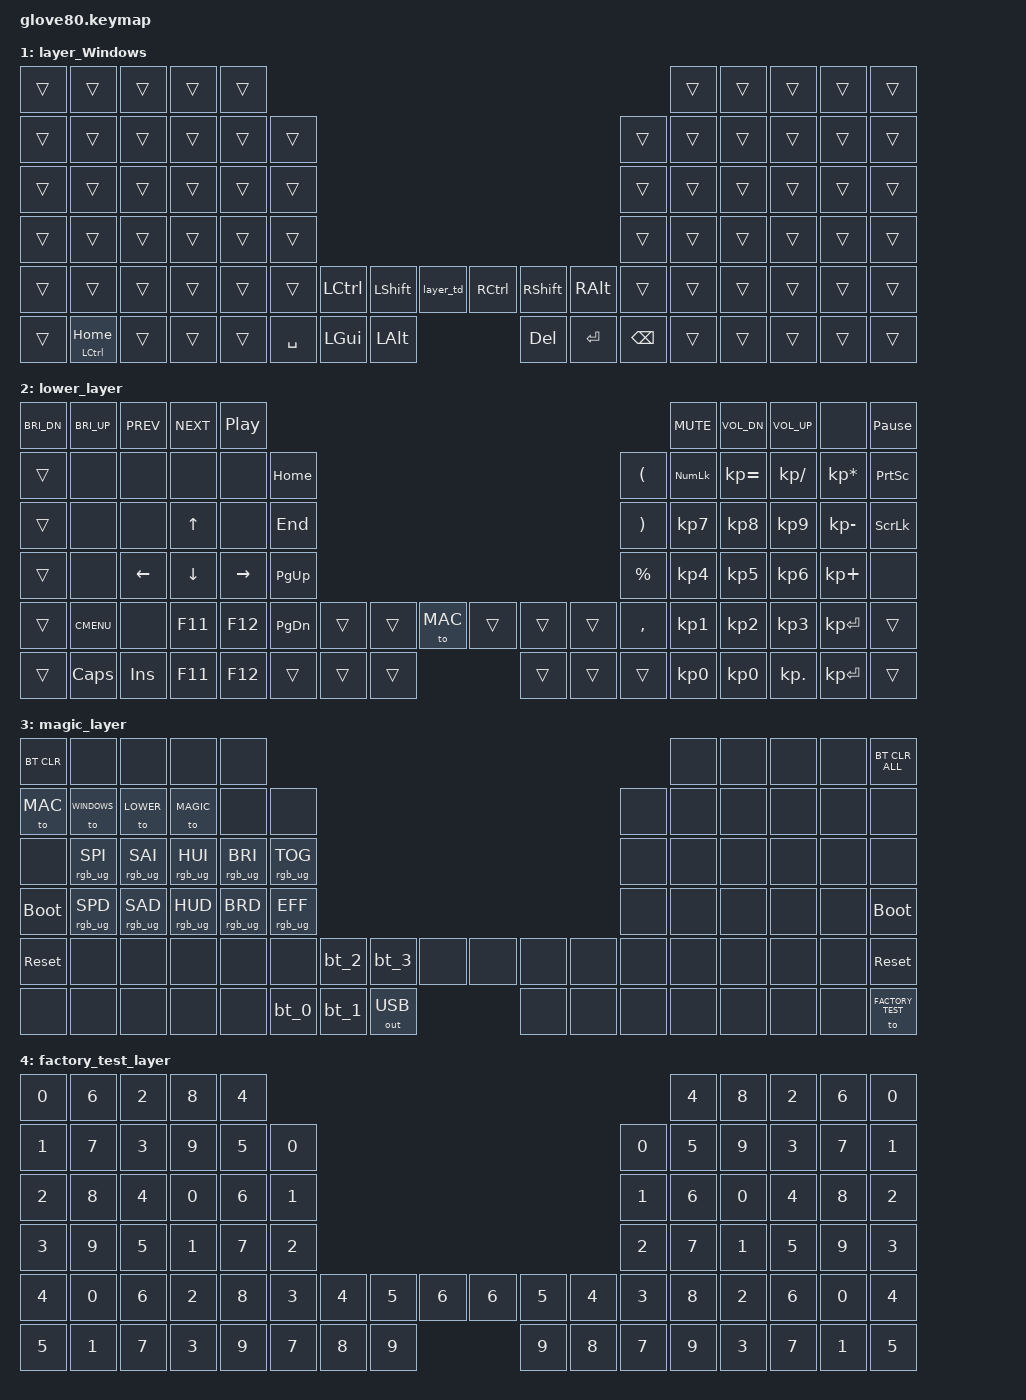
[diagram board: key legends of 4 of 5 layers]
/*
 * Copyright (c) 2020 The ZMK Contributors
 *
 * SPDX-License-Identifier: MIT
 */

#include <behaviors.dtsi>
#include <dt-bindings/zmk/keys.h>
#include <dt-bindings/zmk/bt.h>
#include <dt-bindings/zmk/ext_power.h>
#include <dt-bindings/zmk/outputs.h>
#include <dt-bindings/zmk/rgb.h>

#define HYPER LC(LS(LG(LALT)))

// layers
#define MAC 0
#define WINDOWS 1
#define LOWER 2
#define MAGIC 3
#define FACTORY_TEST 4

// My Personal defines
#define AS(keycode) &tk LS(keycode) keycode     // Autoshift Macro
#define KEYS_L 10 11 12 13 14 15 22 23 24 25 26 27 34 35 36 37 38 39 46 47 48 49 50 51 64 65 66 67 68  // left-hand keys
#define KEYS_R 16 17 18 19 20 21 28 29 30 31 32 33 40 41 42 43 44 45 58 59 60 61 62 63 75 76 77 78 79  // right-hand keys
#define THUMB_L 52 53 54 69 70 71
#define THUMB_R 55 56 57 72 73 74
#define HRM_KEYS_L 35 36 37 38
#define HRM_KEYS_R 41 42 43 44

#define LHRM &lh_pht_bal
#define RHRM &rh_pht_bal

/ {
    behaviors {
        // For the "layer" key, it'd nice to be able to use it as either a shift or a toggle.
        // Configure it as a tap dance, so the first tap (or hold) is a &mo and the second tap is a &to
        layer_td: tap_dance_0 {
            compatible = "zmk,behavior-tap-dance";
            label = "LAYER_TAP_DANCE";
            #binding-cells = <0>;
            tapping-term-ms = <200>;
            bindings = <&mo LOWER>, <&to LOWER>;
        };

        magic: magic_hold_tap {
            compatible = "zmk,behavior-hold-tap";
            label = "MAGIC_HOLD_TAP";
            #binding-cells = <2>;
            flavor = "tap-preferred";
            tapping-term-ms = <200>;
            bindings = <&mo>, <&rgb_ug_status_macro>;
        };
    };

    macros {
        rgb_ug_status_macro: rgb_ug_status_macro_0 {
            label = "RGB_UG_STATUS";
            compatible = "zmk,behavior-macro";
            #binding-cells = <0>;
            bindings
                = <&rgb_ug RGB_STATUS>;
        };

        bt_0: bt_profile_macro_0 {
            label = "BT_0";
            compatible = "zmk,behavior-macro";
            #binding-cells = <0>;
            bindings
                = <&out OUT_BLE>,
                  <&bt BT_SEL 0>;
        };

        bt_1: bt_profile_macro_1 {
            label = "BT_1";
            compatible = "zmk,behavior-macro";
            #binding-cells = <0>;
            bindings
                = <&out OUT_BLE>,
                  <&bt BT_SEL 1>;
        };

        bt_2: bt_profile_macro_2 {
            label = "BT_2";
            compatible = "zmk,behavior-macro";
            #binding-cells = <0>;
            bindings
                = <&out OUT_BLE>,
                  <&bt BT_SEL 2>;
        };

        bt_3: bt_profile_macro_3 {
            label = "BT_3";
            compatible = "zmk,behavior-macro";
            #binding-cells = <0>;
            bindings
                = <&out OUT_BLE>,
                  <&bt BT_SEL 3>;
        };
    };

    /* Custom Defined Behaviors */
    behaviors {
        tk: two_keys{
            compatible = "zmk,behavior-hold-tap";
            label = "TWO_KEYS";
            #binding-cells = <2>;
            tapping_term_ms = <270>;
            quick_tap_ms = <0>;
            flavor = "tap-preferred";
            bindings = <&kp>, <&kp>;
        };

        lh_pht_tui: left_hand_positional_hold_tap {
            compatible = "zmk,behavior-hold-tap";
            label = "LEFT_POSITIONAL_HOLD_TAP";
            #binding-cells = <2>;
            flavor = "tap-unless-interrupted";
            tapping-term-ms = <400>;                        // <---[[produces tap if held longer than tapping-term-ms]]
            quick-tap-ms = <175>;
            global-quick-tap;
            bindings = <&kp>, <&kp>;
            hold-trigger-key-positions = <KEYS_R>;    // <---[[right-hand keys]]
            hold-trigger-on-release;
        };

        rh_pht_tui: right_hand_positional_hold_tap {
            compatible = "zmk,behavior-hold-tap";
            label = "RIGHT_POSITIONAL_HOLD_TAP";
            #binding-cells = <2>;
            flavor = "tap-unless-interrupted";
            tapping-term-ms = <400>;                        // <---[[produces tap if held longer than tapping-term-ms]]
            quick-tap-ms = <175>;
            global-quick-tap;
            bindings = <&kp>, <&kp>;
            hold-trigger-key-positions = <KEYS_L>;    // <---[[left-hand keys]]
            hold-trigger-on-release;
        };

        lh_pht_bal: left_hand_positional_hold_tap_balanced {
            compatible = "zmk,behavior-hold-tap";
            label = "LEFT_POSITIONAL_HOLD_TAP_BALANCED";
            #binding-cells = <2>;
            flavor = "balanced";
            tapping-term-ms = <280>;                        // <---[[produces hold if held longer than tapping-term-ms]]
            quick-tap-ms = <175>;
            global-quick-tap;
            bindings = <&kp>, <&kp>;
            hold-trigger-key-positions = <KEYS_R THUMB_R>;    // <---[[right-hand keys]]
            hold-trigger-on-release;
        };

        rh_pht_bal: right_hand_positional_hold_tap_balanced {
            compatible = "zmk,behavior-hold-tap";
            label = "RIGHT_POSITIONAL_HOLD_TAP_BALANCED";
            #binding-cells = <2>;
            flavor = "balanced";
            tapping-term-ms = <280>;                        // <---[[produces hold if held longer than tapping-term-ms]]
            quick-tap-ms = <175>;
            global-quick-tap;
            bindings = <&kp>, <&kp>;
            hold-trigger-key-positions = <KEYS_L THUMB_L>;    // <---[[left-hand keys]]
            hold-trigger-on-release;
        };

        bhm: balanced_homerow_mods {
            compatible = "zmk,behavior-hold-tap";
            label = "HOMEROW_MODS";
            #binding-cells = <2>;
            tapping-term-ms = <500>;
            quick-tap-ms = <0>;
            flavor = "balanced";
            bindings = <&kp>, <&kp>;
        };
    };


    keymap {
        compatible = "zmk,keymap";

        default_layer_mac {
            // ---------------------------------------------------------------------------------------------------------------------------------
            // |  F1   |  F2 |  F3 |  F4  |  F5  |                                                               |  F6   |  F7   |  F8  |   F9  |  F10 |
            // |  =    |  1  |  2  |  3   |  4   |  5   |                                                 |  6   |   7   |   8   |  9   |   0   |   -  |
            // |  TAB  |  Q  |  W  |  E   |  R   |  T   |                                                 |  Y   |   U   |   I   |  O   |   P   |   \  |
            // |  ESC  |  A  |  S  |  D   |  F   |  G   |                                                 |  H   |   J   |   K   |  L   |   ;   |   '  |
            // |   `   |  Z  |  X  |  C   |  V   |  B   | LSHFT | LCTRL | LOWER | | LGUI  | RCTRL | RSHFT |  N   |   M   |   ,   |  .   |   /   | PGUP |
            // | MAGIC | HOME| END | LEFT | RIGHT|      | BSPC  | DEL   | LALT  | | RALT  | RET   | SPACE |      |  UP   | DOWN  |  [   |   ]   | PGDN |

            bindings = <
          &kp F1       &kp F2            &kp F3           &kp F4        &kp F5                                                                                      &kp F6       &kp F7            &kp F8             &kp F9         &kp F10
          &kp LALT     AS(N1)            AS(N2)           AS(N3)        AS(N4)         AS(N5)                                                                       AS(N6)       AS(N7)            AS(N8)             AS(N9)         AS(N0)          &kp PG_UP
         AS(EQUAL)     &kp Q             &kp W            &kp E         &kp R          &kp T                                                                        &kp Y        &kp U             &kp I              &kp O          AS(SEMI)        AS(MINUS)
     &mt LSHIFT TAB  LHRM LCTRL A     LHRM LALT S      LHRM LGUI D    LHRM LSHFT F     &kp G                                                                        &kp H      RHRM RSHFT J      RHRM RGUI K        RHRM RALT L    RHRM RCTRL P      AS(SQT)
         AS(GRAVE)     &kp Z             &kp X            &kp C         &kp V          &kp B    &kp LGUI   &kp LSHFT   &layer_td  &kp RGUI  &kp RSHFT  &kp RALT     &kp N        &kp M             AS(COMMA)          AS(DOT)        AS(FSLH)        AS(BSLH)
    &magic MAGIC 0  &mt LGUI HOME    &mt LALT END        &kp UP        &kp DOWN                 &kp SPACE  &kp LCTRL   &kp ESC    &kp DEL   &kp RET    &kp BSPC                  &kp LEFT          &kp RIGHT          AS(LBKT)       AS(RBKT)        &kp PG_DN
            >;
        };

        layer_Windows {
            bindings = <
              &trans       &trans       &trans        &trans        &trans                                                                                                      &trans        &trans        &trans        &trans        &trans
              &trans       &trans       &trans        &trans        &trans       &trans                                                                           &trans        &trans        &trans        &trans        &trans        &trans
              &trans       &trans       &trans        &trans        &trans       &trans                                                                           &trans        &trans        &trans        &trans        &trans        &trans
              &trans       &trans       &trans        &trans        &trans       &trans                                                                           &trans        &trans        &trans        &trans        &trans        &trans
              &trans       &trans       &trans        &trans        &trans       &trans   &kp LCTRL  &kp LSHFT  &layer_td      &kp RCTRL  &kp RSHFT  &kp RALT     &trans        &trans        &trans        &trans        &trans        &trans
              &trans   &mt LCTRL HOME   &trans        &trans        &trans                &kp SPACE  &kp LGUI   &kp LALT       &kp DEL    &kp RET    &kp BSPC                   &trans        &trans        &trans        &trans        &trans
            >;
        };

        lower_layer {
            bindings = <
            &kp C_BRI_DN      &kp C_BRI_UP        &kp C_PREV      &kp C_NEXT      &kp C_PP                                                                                                           &kp C_MUTE   &kp C_VOL_DN &kp C_VOL_UP  &none           &kp PAUSE_BREAK
            &trans            &none               &none           &none           &none           &kp HOME                                                                              &kp LPAR     &kp KP_NUM   &kp KP_EQUAL &kp KP_DIVIDE &kp KP_MULTIPLY &kp PSCRN
            &trans            &none               &none           &kp UP          &none           &kp END                                                                               &kp RPAR     &kp KP_N7    &kp KP_N8    &kp KP_N9     &kp KP_MINUS    &kp SLCK
            &trans            &none               &kp LEFT        &kp DOWN        &kp RIGHT       &kp PG_UP                                                                             &kp PRCNT    &kp KP_N4    &kp KP_N5    &kp KP_N6     &kp KP_PLUS     &none
            &trans            &kp K_CMENU         &none           &kp F11         &kp F12         &kp PG_DN       &trans      &trans      &to MAC     &trans      &trans      &trans    &kp COMMA    &kp KP_N1    &kp KP_N2    &kp KP_N3     &kp KP_ENTER    &trans
            &trans            &kp CAPS            &kp INS         &kp F11         &kp F12                         &trans      &trans      &trans      &trans      &trans      &trans                 &kp KP_N0    &kp KP_N0    &kp KP_DOT    &kp KP_ENTER    &trans
            >;
        };

        magic_layer {
            bindings = <
            &bt BT_CLR        &none               &none           &none           &none                                                                                                           &none      &none      &none      &none      &bt BT_CLR_ALL
            &to MAC           &to WINDOWS         &to LOWER       &to MAGIC       &none           &none                                                                                &none      &none      &none      &none      &none      &none
            &none             &rgb_ug RGB_SPI     &rgb_ug RGB_SAI &rgb_ug RGB_HUI &rgb_ug RGB_BRI &rgb_ug RGB_TOG                                                                      &none      &none      &none      &none      &none      &none
            &bootloader       &rgb_ug RGB_SPD     &rgb_ug RGB_SAD &rgb_ug RGB_HUD &rgb_ug RGB_BRD &rgb_ug RGB_EFF                                                                      &none      &none      &none      &none      &none      &bootloader
            &sys_reset        &none               &none           &none           &none           &none           &bt_2     &bt_3     &none            &none     &none     &none       &none      &none      &none      &none      &none      &sys_reset
            &none             &none               &none           &none           &none                           &bt_0     &bt_1     &out OUT_USB     &none     &none     &none                  &none      &none      &none      &none      &to FACTORY_TEST
            >;
        };

        factory_test_layer {
            bindings = <
            &kp N0   &kp N6   &kp N2   &kp N8   &kp N4                                                                              &kp N4   &kp N8   &kp N2   &kp N6   &kp N0
            &kp N1   &kp N7   &kp N3   &kp N9   &kp N5   &kp N0                                                            &kp N0   &kp N5   &kp N9   &kp N3   &kp N7   &kp N1
            &kp N2   &kp N8   &kp N4   &kp N0   &kp N6   &kp N1                                                            &kp N1   &kp N6   &kp N0   &kp N4   &kp N8   &kp N2
            &kp N3   &kp N9   &kp N5   &kp N1   &kp N7   &kp N2                                                            &kp N2   &kp N7   &kp N1   &kp N5   &kp N9   &kp N3
            &kp N4   &kp N0   &kp N6   &kp N2   &kp N8   &kp N3   &kp N4   &kp N5   &kp N6      &kp N6   &kp N5   &kp N4   &kp N3   &kp N8   &kp N2   &kp N6   &kp N0   &kp N4
            &kp N5   &kp N1   &kp N7   &kp N3   &kp N9            &kp N7   &kp N8   &kp N9      &kp N9   &kp N8   &kp N7            &kp N9   &kp N3   &kp N7   &kp N1   &kp N5
            >;
        };
    };
};
